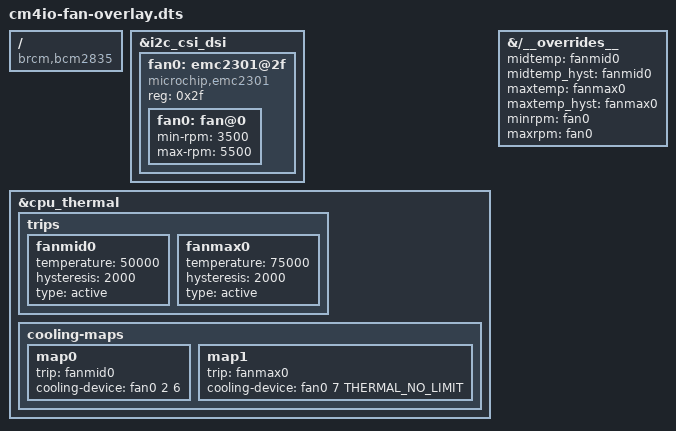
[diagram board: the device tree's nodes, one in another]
/*
 * Overlay for EMC2301 fan control chip on the Raspberry Pi Compute Module 4 IO board.
 */
/dts-v1/;
/plugin/;

/ {
        compatible = "brcm,bcm2835";

        fragment@0 {
                target = <&i2c_csi_dsi>;
                __overlay__ {
                        fan0: emc2301@2f {
                                reg = <0x2f>;
                                compatible = "microchip,emc2301";
                                #cooling-cells = <0x02>;

                                fan0: fan@0 {
                                        min-rpm = /bits/ 16 <3500>;
                                        max-rpm = /bits/ 16 <5500>;
                                };
                        };
                };
        };

        fragment@1 {
                target = <&cpu_thermal>;
                polling-delay = <2000>; /* milliseconds */
                __overlay__ {
                        trips {
                                fanmid0: fanmid0 {
                                        temperature = <50000>;
                                        hysteresis = <2000>;
                                        type = "active";
                                };
                                fanmax0: fanmax0 {
                                        temperature = <75000>;
                                        hysteresis = <2000>;
                                        type = "active";
                                };
                        };
                        cooling-maps {
                                map0 {
                                        trip = <&fanmid0>;
                                        cooling-device = <&fan0 2 6>;
                                };
                                map1 {
                                        trip = <&fanmax0>;
                                        cooling-device = <&fan0 7 THERMAL_NO_LIMIT>;
                                };
                        };
                };
        };

        fragment@2 {
                target-path = "/__overrides__";
                __overlay__ {
                        midtemp =       <&fanmid0>,"temperature:0";
                        midtemp_hyst =  <&fanmid0>,"hysteresis:0";
                        maxtemp =       <&fanmax0>,"temperature:0";
                        maxtemp_hyst =  <&fanmax0>,"hysteresis:0";
                        minrpm =        <&fan0>,"min-rpm:0";
                        maxrpm =        <&fan0>,"max-rpm:0";
                };
        };

        __overrides__ {
                midtemp =       <&fanmid0>,"temperature:0";
                midtemp_hyst =  <&fanmid0>,"hysteresis:0";
                maxtemp =       <&fanmax0>,"temperature:0";
                maxtemp_hyst =  <&fanmax0>,"hysteresis:0";
                minrpm =        <&fan0>,"min-rpm:0";
                maxrpm =        <&fan0>,"max-rpm:0";
        };
};
